# CY8C4245AXI_483 register map
File version: 0.1
PSoC 4200
Registers are 32-bit, read-write, no defined reset value unless marked. A register's access mark holds for its fields unless they carry their own. Offsets are from the block's base; lines under a group give offsets from that group; [hi:lo] are bit positions; {n}, {i} and the like mark numbered series; 'fields as' and 'values as' point back to an identical list; <NAME> marks a mode.

## Memory map
0x00000000 PWM_1
0x00000000 UART
0x00000000 PWM_2
0x00000000 I2C — Serial Communication Block
0x00000000 Timer_1
0x00000000 ADC — Sequencing SAR ADC

## PWM_1
Base 0x00000000
0x40050108 COUNTER — Current counter value
0x4005010C CC — Compare / capture value
0x40050110 CC_BUF — Compare / capture buffer value
0x40050114 PERIOD — Period value
0x40050118 PERIOD_BUF — Period buffer value

## UART
Base 0x00000000
0x400F0021 RX_UART_RX_ADDRESS1 8-bit — RX Address1 Register
0x400F0031 RX_UART_RX_ADDRESS2 8-bit — RX Address2 Register
0x400F0041 RX_UART_RX_DATA 8-bit — RX Data Register
0x400F0042 TX_UART_TX_DATA 8-bit — TX Data Register
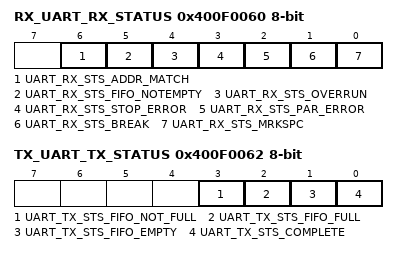
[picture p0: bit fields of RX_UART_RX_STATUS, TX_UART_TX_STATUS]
0x400F0060 RX_UART_RX_STATUS 8-bit — RX status register
  [6] UART_RX_STS_ADDR_MATCH ro, [5] UART_RX_STS_FIFO_NOTEMPTY ro, [4] UART_RX_STS_OVERRUN ro, [3] UART_RX_STS_STOP_ERROR ro, [2] UART_RX_STS_PAR_ERROR ro, [1] UART_RX_STS_BREAK ro, [0] UART_RX_STS_MRKSPC ro
0x400F0062 TX_UART_TX_STATUS 8-bit — TX status register
  [3] UART_TX_STS_FIFO_NOT_FULL ro, [2] UART_TX_STS_FIFO_FULL ro, [1] UART_TX_STS_FIFO_EMPTY ro, [0] UART_TX_STS_COMPLETE ro

## PWM_2
Base 0x00000000
0x40050188 COUNTER — Current counter value
0x4005018C CC — Compare / capture value
0x40050190 CC_BUF — Compare / capture buffer value
0x40050194 PERIOD — Period value
0x40050198 PERIOD_BUF — Period buffer value

## Timer_1
Base 0x00000000
0x40050148 COUNTER — Current counter value
0x4005014C CC — Compare / capture value
0x40050150 CC_BUF — Compare / capture buffer value
0x40050154 PERIOD — Period value
0x40050158 PERIOD_BUF — Period buffer value
